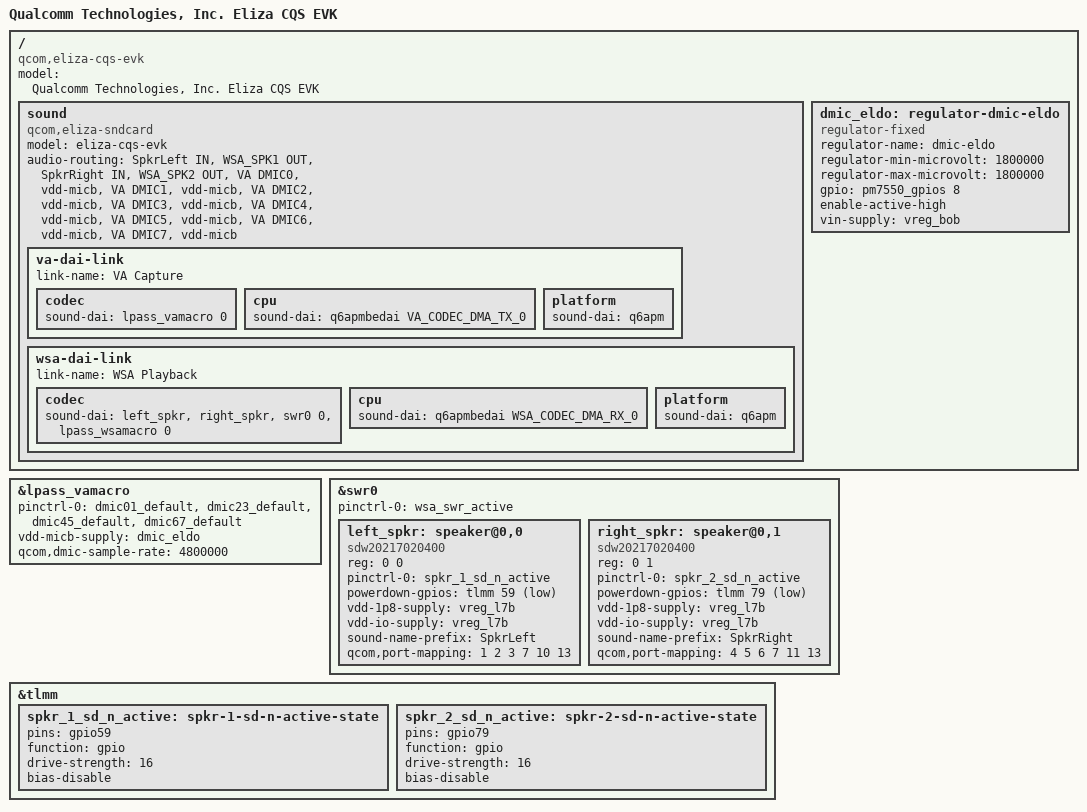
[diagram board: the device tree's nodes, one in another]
// SPDX-License-Identifier: BSD-3-Clause
/*
 * Copyright (c) Qualcomm Technologies, Inc. and/or its subsidiaries.
 */

/dts-v1/;

#include <dt-bindings/sound/qcom,q6dsp-lpass-ports.h>

#include "eliza-cqs-som.dtsi"
#include "eliza-evk.dtsi"

/ {
	model = "Qualcomm Technologies, Inc. Eliza CQS EVK";
	compatible = "qcom,eliza-cqs-evk", "qcom,eliza-cqs-som", "qcom,eliza";

	sound {
		compatible = "qcom,eliza-sndcard", "qcom,sm8450-sndcard";
		model = "eliza-cqs-evk";

		audio-routing = "SpkrLeft IN", "WSA_SPK1 OUT",
				"SpkrRight IN", "WSA_SPK2 OUT",
				"VA DMIC0", "vdd-micb",
				"VA DMIC1", "vdd-micb",
				"VA DMIC2", "vdd-micb",
				"VA DMIC3", "vdd-micb",
				"VA DMIC4", "vdd-micb",
				"VA DMIC5", "vdd-micb",
				"VA DMIC6", "vdd-micb",
				"VA DMIC7", "vdd-micb";

		va-dai-link {
			link-name = "VA Capture";

			codec {
				sound-dai = <&lpass_vamacro 0>;
			};

			cpu {
				sound-dai = <&q6apmbedai VA_CODEC_DMA_TX_0>;
			};

			platform {
				sound-dai = <&q6apm>;
			};
		};

		wsa-dai-link {
			link-name = "WSA Playback";

			codec {
				sound-dai = <&left_spkr>, <&right_spkr>,
					    <&swr0 0>, <&lpass_wsamacro 0>;
			};

			cpu {
				sound-dai = <&q6apmbedai WSA_CODEC_DMA_RX_0>;
			};

			platform {
				sound-dai = <&q6apm>;
			};
		};
	};

	dmic_eldo: regulator-dmic-eldo {
		compatible = "regulator-fixed";
		regulator-name = "dmic-eldo";
		regulator-min-microvolt = <1800000>;
		regulator-max-microvolt = <1800000>;
		gpio = <&pm7550_gpios 8 GPIO_ACTIVE_HIGH>;
		enable-active-high;
		vin-supply = <&vreg_bob>;
	};
};

&lpass_vamacro {
	pinctrl-0 = <&dmic01_default>, <&dmic23_default>,
		    <&dmic45_default>, <&dmic67_default>;
	pinctrl-names = "default";

	vdd-micb-supply = <&dmic_eldo>;
	qcom,dmic-sample-rate = <4800000>;
};

&swr0 {
	pinctrl-0 = <&wsa_swr_active>;
	pinctrl-names = "default";

	status = "okay";

	/* WSA8845, Speaker Left */
	left_spkr: speaker@0,0 {
		compatible = "sdw20217020400";
		reg = <0 0>;
		pinctrl-0 = <&spkr_1_sd_n_active>;
		pinctrl-names = "default";
		powerdown-gpios = <&tlmm 59 GPIO_ACTIVE_LOW>;
		vdd-1p8-supply = <&vreg_l7b>;
		vdd-io-supply = <&vreg_l7b>;

		#sound-dai-cells = <0>;
		sound-name-prefix = "SpkrLeft";

		/*
		 * WSA8845 Port 1 (DAC)     <=> SWR0 Port 1  (SPKR_L)
		 * WSA8845 Port 2 (COMP)    <=> SWR0 Port 2  (SPKR_L_COMP)
		 * WSA8845 Port 3 (BOOST)   <=> SWR0 Port 3  (SPKR_L_BOOST)
		 * WSA8845 Port 4 (PBR)     <=> SWR0 Port 7  (PBR)
		 * WSA8845 Port 5 (VISENSE) <=> SWR0 Port 10 (SPKR_L_VI)
		 * WSA8845 Port 6 (CPS)     <=> SWR0 Port 13 (CPS)
		 */
		qcom,port-mapping = <1 2 3 7 10 13>;
	};

	/* WSA8845, Speaker Right */
	right_spkr: speaker@0,1 {
		compatible = "sdw20217020400";
		reg = <0 1>;
		pinctrl-0 = <&spkr_2_sd_n_active>;
		pinctrl-names = "default";
		powerdown-gpios = <&tlmm 79 GPIO_ACTIVE_LOW>;
		vdd-1p8-supply = <&vreg_l7b>;
		vdd-io-supply = <&vreg_l7b>;

		#sound-dai-cells = <0>;
		sound-name-prefix = "SpkrRight";

		/*
		 * WSA8845 Port 1 (DAC)     <=> SWR0 Port 4  (SPKR_R)
		 * WSA8845 Port 2 (COMP)    <=> SWR0 Port 5  (SPKR_R_COMP)
		 * WSA8845 Port 3 (BOOST)   <=> SWR0 Port 6  (SPKR_R_BOOST)
		 * WSA8845 Port 4 (PBR)     <=> SWR0 Port 7  (PBR)
		 * WSA8845 Port 5 (VISENSE) <=> SWR0 Port 11 (SPKR_R_VI)
		 * WSA8845 Port 6 (CPS)     <=> SWR0 Port 13 (CPS)
		 */
		qcom,port-mapping = <4 5 6 7 11 13>;
	};
};

&tlmm {
	spkr_1_sd_n_active: spkr-1-sd-n-active-state {
		pins = "gpio59";
		function = "gpio";
		drive-strength = <16>;
		bias-disable;
	};

	spkr_2_sd_n_active: spkr-2-sd-n-active-state {
		pins = "gpio79";
		function = "gpio";
		drive-strength = <16>;
		bias-disable;
	};
};
